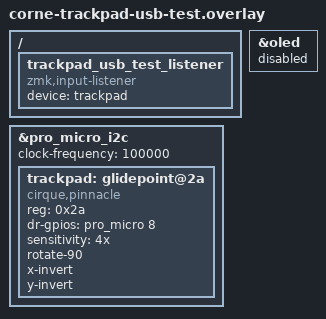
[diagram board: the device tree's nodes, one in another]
#include "../corne-trackpad/corne_trackpad.dtsi"

&pro_micro_i2c {
    status = "okay";
    clock-frequency = <100000>;

    trackpad: glidepoint@2a {
        compatible = "cirque,pinnacle";
        reg = <0x2a>;
        status = "okay";
        dr-gpios = <&pro_micro 8 (GPIO_ACTIVE_HIGH)>;
        sensitivity = "4x";
        rotate-90;
        x-invert;
        y-invert;
    };
};

&oled {
    status = "disabled";
};

/ {
    trackpad_usb_test_listener: trackpad_usb_test_listener {
        compatible = "zmk,input-listener";
        device = <&trackpad>;
    };
};
